VERSION ""

NS_ :

BS_:

BU_: XXX EPS ESP SCM

BO_ 37 STEER_ANGLE_SENSOR: 32 XXX
 SG_ STEER_ANGLE : 3|12@0- (1.5,0) [-500|500] "deg" XXX
 SG_ STEER_FRACTION : 39|4@0- (0.1,0) [-0.7|0.7] "deg" XXX
 SG_ STEER_RATE : 35|12@0- (1,0) [-2000|2000] "deg/s" XXX
 SG_ CHECKSUM : 63|8@0+ (1,0) [0|255] "" XXX

BO_ 48 EPS_STATUS: 32 EPS
 SG_ EPS_FAULT_INHIBIT : 50|1@0+ (1,0) [0|1] "" XXX
 SG_ DRIVER_TORQUE_INVALID : 48|1@0+ (1,0) [0|1] "" XXX
 SG_ STEERING_WHEEL_TORQUE_COARSE : 71|8@0- (0.1,0) [-12.8|12.7] "Nm" XXX
 SG_ STEERING_WHEEL_TORQUE_FINE : 139|4@0- (0.01,0) [-0.08|0.07] "Nm" XXX
 SG_ COOPERATIVE_COMMAND_INHIBIT : 128|1@0+ (1,0) [0|1] "" XXX
 SG_ COOPERATIVE_ANGLE_INHIBIT : 152|1@0+ (1,0) [0|1] "" XXX
 SG_ CHECKSUM : 63|8@0+ (1,0) [0|255] "" XXX

BO_ 254 CRUISE_BUTTONS: 32 XXX
 SG_ MAIN_BUTTON : 58|1@0+ (1,0) [0|1] "" XXX
 SG_ RES_BUTTON : 31|1@0+ (1,0) [0|1] "" XXX
 SG_ RES_BUTTON_MIRROR_N : 55|1@0+ (1,0) [0|1] "" XXX
 SG_ SET_BUTTON : 39|1@0+ (1,0) [0|1] "" XXX
 SG_ SET_BUTTON_MIRROR_N : 62|1@0+ (1,0) [0|1] "" XXX
 SG_ CANCEL_BUTTON : 38|1@0+ (1,0) [0|1] "" XXX
 SG_ CANCEL_BUTTON_MIRROR_N : 61|1@0+ (1,0) [0|1] "" XXX

BO_ 129 CONTROL_RESULT: 32 XXX
 SG_ LONGITUDINAL_RESULT_ID : 53|6@0+ (1,0) [0|63] "" XXX
 SG_ REQUEST_LOSS : 92|1@0+ (1,0) [0|1] "" XXX
 SG_ LATERAL_RESULT_ID : 109|6@0+ (1,0) [0|63] "" XXX
 SG_ CHECKSUM : 63|8@0+ (1,0) [0|255] "" XXX

BO_ 138 CONTROL_REQUEST: 32 XXX
 SG_ UNKNOWN_1 : 7|28@0+ (1,0) [0|268435455] "" XXX
 SG_ CRUISE_OPERATING_LATCH : 27|1@0+ (1,0) [0|1] "" XXX
 SG_ UNKNOWN_2 : 26|3@0+ (1,0) [0|7] "" XXX
 SG_ SET_ME_1 : 39|1@0+ (1,0) [0|1] "" XXX
 SG_ PCS_BRAKE_REQUEST : 38|1@0+ (1,0) [0|1] "" XXX
 SG_ DELAYED_HOLD_STATE : 37|1@0+ (1,0) [0|1] "" XXX
 SG_ UNKNOWN_4 : 36|13@0+ (1,0) [0|8191] "" XXX
 SG_ LONGITUDINAL_REQUEST_ID_UPPER : 55|6@0+ (1,0) [0|63] "" XXX
 SG_ LONGITUDINAL_ALLOCATION_METHOD_UPPER : 49|2@0+ (1,0) [0|3] "" XXX
 SG_ CHECKSUM : 63|8@0+ (1,0) [0|255] "" XXX
 SG_ LONGITUDINAL_REQUEST_ACCEL_UPPER : 71|16@0- (0.001,0) [-32.768|32.767] "m/s^2" XXX
 SG_ SET_SPEED : 87|8@0+ (1,0) [0|255] "km/h" XXX
 SG_ LONGITUDINAL_REQUEST_ACCEL_LOWER : 95|16@0- (0.001,0) [-32.768|32.767] "m/s^2" XXX
 SG_ SET_ME_X7FFF : 111|16@0+ (1,0) [0|65535] "" XXX
 SG_ UNKNOWN_5 : 127|8@0+ (1,0) [0|255] "" XXX
 SG_ SET_ME_X7FFF_2 : 135|16@0+ (1,0) [0|65535] "" XXX
 SG_ LATERAL_REQUEST_PINION_ANGLE : 151|16@0- (0.001000121519,0) [-32.772|32.771] "rad" XXX
 SG_ CRUISE_STATE_MIRROR : 167|2@0+ (1,0) [0|3] "" XXX
 SG_ UNKNOWN_6 : 165|8@0+ (1,0) [0|255] "" XXX
 SG_ LATERAL_REQUEST_ID : 173|6@0+ (1,0) [0|63] "" XXX
 SG_ UNKNOWN_7 : 183|3@0+ (1,0) [0|7] "" XXX
 SG_ CRUISE_REQUEST_ACTIVE : 180|1@0+ (1,0) [0|1] "" XXX
 SG_ UNKNOWN_8 : 179|12@0+ (1,0) [0|4095] "" XXX
 SG_ LATERAL_ASSIST_GAIN : 199|8@0+ (0.01,0) [0|2.55] "" XXX
 SG_ LATERAL_DAMPING_GAIN : 207|8@0+ (0.01,0) [0|2.55] "" XXX
 SG_ UNKNOWN_9 : 215|2@0+ (1,0) [0|3] "" XXX
 SG_ REQUEST_SEQUENCE : 213|6@0+ (1,0) [0|63] "" XXX
 SG_ UNKNOWN_10 : 223|8@0+ (1,0) [0|255] "" XXX
 SG_ AUTHENTICATOR : 227|28@0+ (1,0) [0|268435455] "" XXX
 SG_ RESET_FLAG : 229|2@0+ (1,0) [0|3] "" XXX
 SG_ MSG_CNT_LOWER : 231|2@0+ (1,0) [0|3] "" XXX

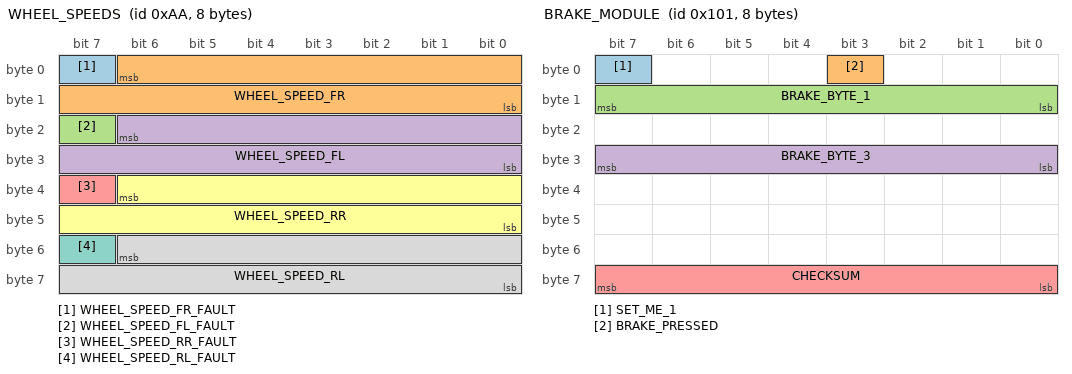
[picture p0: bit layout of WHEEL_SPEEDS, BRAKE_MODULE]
BO_ 170 WHEEL_SPEEDS: 8 XXX
 SG_ WHEEL_SPEED_FR_FAULT : 7|1@0+ (1,0) [0|1] "" XXX
 SG_ WHEEL_SPEED_FR : 6|15@0+ (0.01,-67.67) [-67.67|260] "km/h" XXX
 SG_ WHEEL_SPEED_FL_FAULT : 23|1@0+ (1,0) [0|1] "" XXX
 SG_ WHEEL_SPEED_FL : 22|15@0+ (0.01,-67.67) [-67.67|260] "km/h" XXX
 SG_ WHEEL_SPEED_RR_FAULT : 39|1@0+ (1,0) [0|1] "" XXX
 SG_ WHEEL_SPEED_RR : 38|15@0+ (0.01,-67.67) [-67.67|260] "km/h" XXX
 SG_ WHEEL_SPEED_RL_FAULT : 55|1@0+ (1,0) [0|1] "" XXX
 SG_ WHEEL_SPEED_RL : 54|15@0+ (0.01,-67.67) [-67.67|260] "km/h" XXX

BO_ 257 BRAKE_MODULE: 8 XXX
 SG_ SET_ME_1 : 7|1@0+ (1,0) [0|1] "" XXX
 SG_ BRAKE_PRESSED : 3|1@0+ (1,0) [0|1] "" XXX
 SG_ BRAKE_BYTE_1 : 15|8@0+ (1,0) [0|255] "" XXX
 SG_ BRAKE_BYTE_3 : 31|8@0+ (1,0) [0|255] "" XXX
 SG_ CHECKSUM : 63|8@0+ (1,0) [0|255] "" XXX

BO_ 278 GAS_PEDAL: 8 XXX
 SG_ GAS_PEDAL_USER : 15|8@0+ (0.005,0) [0|1.275] "" XXX

BO_ 295 GEAR_PACKET_HYBRID: 8 XXX
 SG_ GEAR : 47|4@0+ (1,0) [0|15] "" XXX
 SG_ CHECKSUM : 63|8@0+ (1,0) [0|255] "" XXX

BO_ 959 GEAR_PACKET: 8 XXX
 SG_ GEAR : 7|8@0+ (1,0) [0|255] "" XXX

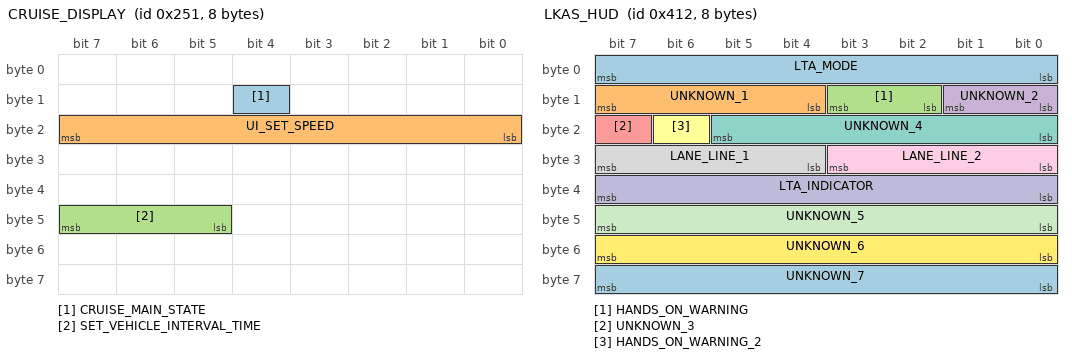
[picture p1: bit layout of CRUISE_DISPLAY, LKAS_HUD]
BO_ 593 CRUISE_DISPLAY: 8 XXX
 SG_ CRUISE_MAIN_STATE : 12|1@0+ (1,0) [0|1] "" XXX
 SG_ UI_SET_SPEED : 23|8@0+ (1,0) [0|255] "" XXX
 SG_ SET_VEHICLE_INTERVAL_TIME : 47|3@0+ (1,0) [1|4] "" XXX

BO_ 636 CRUISE_STATUS: 8 XXX
 SG_ CRUISE_MODE : 1|2@0+ (1,0) [0|3] "" XXX

BO_ 741 SEATBELT_STATUS: 8 XXX
 SG_ SEATBELT_DRIVER_UNLATCHED : 22|1@0+ (1,0) [0|1] "" XXX

BO_ 1042 LKAS_HUD: 8 XXX
 SG_ LTA_MODE : 7|8@0+ (1,0) [0|255] "" XXX
 SG_ UNKNOWN_1 : 15|4@0+ (1,0) [0|15] "" XXX
 SG_ HANDS_ON_WARNING : 11|2@0+ (1,0) [0|3] "" XXX
 SG_ UNKNOWN_2 : 9|2@0+ (1,0) [0|3] "" XXX
 SG_ UNKNOWN_3 : 23|1@0+ (1,0) [0|1] "" XXX
 SG_ HANDS_ON_WARNING_2 : 22|1@0+ (1,0) [0|1] "" XXX
 SG_ UNKNOWN_4 : 21|6@0+ (1,0) [0|63] "" XXX
 SG_ LANE_LINE_1 : 31|4@0+ (1,0) [0|15] "" XXX
 SG_ LANE_LINE_2 : 27|4@0+ (1,0) [0|15] "" XXX
 SG_ LTA_INDICATOR : 39|8@0+ (1,0) [0|255] "" XXX
 SG_ UNKNOWN_5 : 47|8@0+ (1,0) [0|255] "" XXX
 SG_ UNKNOWN_6 : 55|8@0+ (1,0) [0|255] "" XXX
 SG_ UNKNOWN_7 : 63|8@0+ (1,0) [0|255] "" XXX

BO_ 951 ESP_CONTROL: 8 ESP
 SG_ TC_DISABLED : 13|1@0+ (1,0) [0|1] "" XXX
 SG_ BRAKE_HOLD_ACTIVE : 36|1@0+ (1,0) [0|1] "" XXX

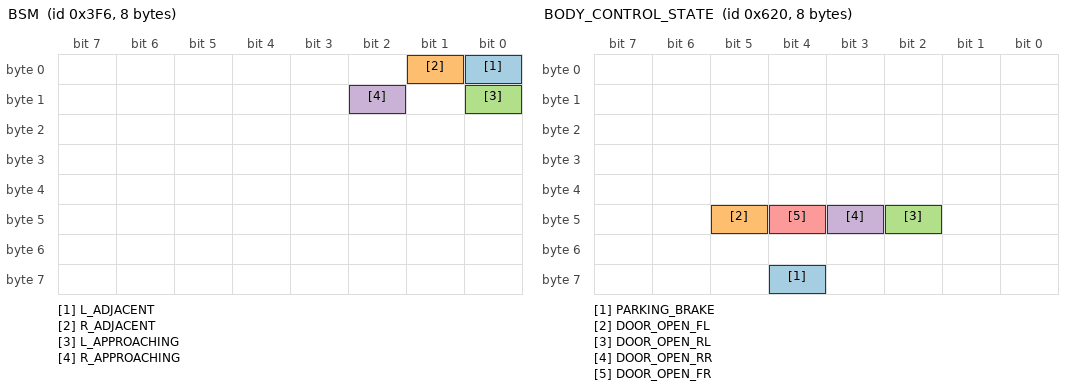
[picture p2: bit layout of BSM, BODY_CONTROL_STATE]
BO_ 1014 BSM: 8 XXX
 SG_ L_ADJACENT : 0|1@0+ (1,0) [0|1] "" XXX
 SG_ R_ADJACENT : 1|1@0+ (1,0) [0|1] "" XXX
 SG_ L_APPROACHING : 8|1@0+ (1,0) [0|1] "" XXX
 SG_ R_APPROACHING : 10|1@0+ (1,0) [0|1] "" XXX

BO_ 1310 READY_STATUS: 8 XXX
 SG_ READY_STATUS : 7|1@0+ (1,0) [0|1] "" XXX

BO_ 1454 PCS_HUD: 32 XXX
 SG_ FCW : 18|1@0+ (1,0) [0|1] "" XXX

BO_ 1552 BODY_CONTROL_STATE_2: 8 XXX
 SG_ UI_SPEED : 23|8@0+ (1,0) [0|255] "km/h" XXX
 SG_ UNITS : 63|3@0+ (1,0) [0|4] "" XXX

BO_ 1556 BLINKERS_STATE: 8 XXX
 SG_ HAZARD_LIGHT : 27|1@0+ (1,0) [0|1] "" XXX
 SG_ TURN_SIGNALS : 29|2@0+ (1,0) [0|3] "" XXX

BO_ 1568 BODY_CONTROL_STATE: 8 XXX
 SG_ PARKING_BRAKE : 60|1@0+ (1,0) [0|1] "" XXX
 SG_ DOOR_OPEN_FL : 45|1@0+ (1,0) [0|1] "" XXX
 SG_ DOOR_OPEN_RL : 42|1@0+ (1,0) [0|1] "" XXX
 SG_ DOOR_OPEN_RR : 43|1@0+ (1,0) [0|1] "" XXX
 SG_ DOOR_OPEN_FR : 44|1@0+ (1,0) [0|1] "" XXX

BO_ 1570 LIGHT_STALK: 8 SCM
 SG_ AUTO_HIGH_BEAM : 37|1@0+ (1,0) [0|1] "" XXX

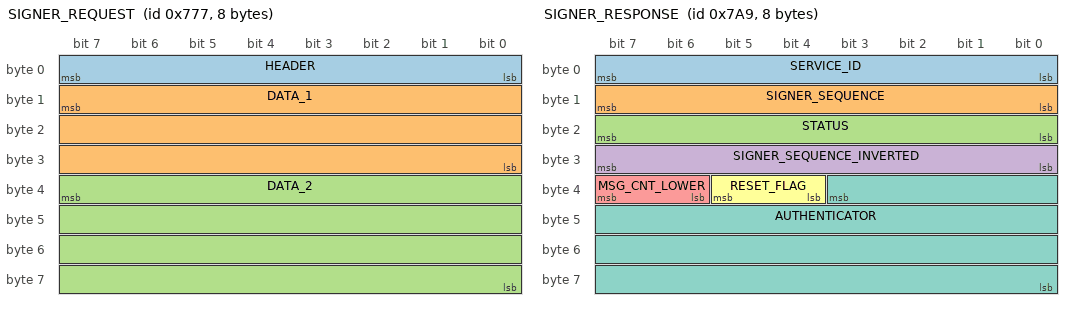
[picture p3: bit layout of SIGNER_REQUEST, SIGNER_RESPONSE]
BO_ 1911 SIGNER_REQUEST: 8 XXX
 SG_ HEADER : 7|8@0+ (1,0) [0|255] "" XXX
 SG_ DATA_1 : 15|24@0+ (1,0) [0|16777215] "" XXX
 SG_ DATA_2 : 39|32@0+ (1,0) [0|4294967295] "" XXX

BO_ 1961 SIGNER_RESPONSE: 8 EPS
 SG_ SERVICE_ID : 7|8@0+ (1,0) [0|255] "" XXX
 SG_ SIGNER_SEQUENCE : 15|8@0+ (1,0) [0|255] "" XXX
 SG_ STATUS : 23|8@0+ (1,0) [0|255] "" XXX
 SG_ SIGNER_SEQUENCE_INVERTED : 31|8@0+ (1,0) [0|255] "" XXX
 SG_ MSG_CNT_LOWER : 39|2@0+ (1,0) [0|3] "" XXX
 SG_ RESET_FLAG : 37|2@0+ (1,0) [0|3] "" XXX
 SG_ AUTHENTICATOR : 35|28@0+ (1,0) [0|268435455] "" XXX
VAL_ 295 GEAR 0 "P" 1 "R" 2 "N" 3 "D" 4 "B" ;
VAL_ 959 GEAR 128 "P" 64 "R" 32 "N" 16 "D" ;
VAL_ 1556 TURN_SIGNALS 3 "none" 2 "right" 1 "left";
VAL_ 636 CRUISE_MODE 0 "UNSPECIFIED" 1 "ADAPTIVE" 2 "CONVENTIONAL";
VAL_ 138 LATERAL_REQUEST_ID 27 "Remote Parking" 25 "AP" 19 "PDA" 18 "SDG" 11 "LTA/LCA" 10 "Hands Off LTA" 4 "LDA" 1 "PCS" 0 "No Request";
VAL_ 138 LONGITUDINAL_ALLOCATION_METHOD_UPPER 3 "Brake Only" 2 "Engine and Brake 2" 1 "Engine and Brake 1" 0 "Engine Only";
CM_ SG_ 48 STEERING_WHEEL_TORQUE_FINE "Driver torque = STEERING_WHEEL_TORQUE_COARSE + STEERING_WHEEL_TORQUE_FINE";
CM_ SG_ 129 REQUEST_LOSS "Set ~90 ms after the last valid CONTROL_REQUEST, a cruise fault latches until restart if it stays set for ~1 s";
CM_ SG_ 138 LATERAL_REQUEST_PINION_ANGLE "1024/17870 deg per count";
CM_ SG_ 138 AUTHENTICATOR "Truncated 28-bit SecOC MAC";
CM_ SG_ 138 PCS_BRAKE_REQUEST "Set only in the FRC's PCS braking requests";
CM_ SG_ 636 CRUISE_MODE "Selected mode, independent of cruise-main and engagement. Zero observed during startup";
CM_ SG_ 1454 FCW "PCS warning";
CM_ BO_ 1911 "Requests to the EPS-resident SecOC signer. HEADER 0x80-0xB0 | sequence nibble: fragment 0-3 of a 28-byte CONTROL_REQUEST, 0x07: arm (DATA_1 0xC9A801) or release (0xC9A800) openpilot's CONTROL_REQUEST";
CM_ BO_ 1961 "Signer response with the SecOC trailer for the CONTROL_REQUEST with this SIGNER_SEQUENCE";
CM_ SG_ 1042 LANE_LINE_1 "1 = recognized, 2 = missing, 4 = recognized while active";
VAL_ 1042 LTA_MODE 20 "active" 18 "available" 16 "off" ;
VAL_ 1042 LTA_INDICATOR 2 "available" 1 "active" 0 "off" ;
